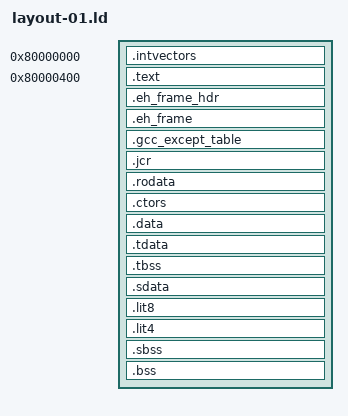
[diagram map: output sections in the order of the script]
/* ========================================================================
 *
 * n64.ld -- Libdragon linker script
 *
 * Originally based on n64ld.x, developed by Frank Somers <frank@g0dev.com>,
 * with modifications by hcs (halleyscometsoftware@hotmail.com),
 * released under the Unlicense.
 * ========================================================================
 */

OUTPUT_FORMAT ("elf32-bigmips", "elf32-bigmips", "elf32-littlemips")
OUTPUT_ARCH (mips)
EXTERN (_start)
ENTRY (_start)

PHDRS
{
    irq PT_LOAD AT ( 0x80000000 );
    main PT_LOAD AT ( 0x80000400 );
}

SECTIONS {
    .intvectors 0x80000000 : {
        . = ALIGN(32);
        KEEP(*(.intvectors))
        __intvectors_end = .;
    } :irq

    /* The text section carries the app code and its relocation addr is
    * the first byte of the cart domain in cached, unmapped memory
    */
    .text 0x80000400 : {
        __text_start = .;
        *(.boot)
        . = ALIGN(16);
        *(.text)
        /* MipsFit: verified unique input sections; GC remains enabled */
        *(.text._ZN3e64L16mesh_composePartEPKNS_4MeshEPKNS_15RenderTransformEPNS_7Vector3EPNS_10QuaternionES7_)
        *(.text._ZN3e6412water_updateEf)
        *(.text.joypad_get_axis_pressed)
        *(.text._ZN3e6420quaternion_toMatrix3EPKNS_10QuaternionE)
        *(.text._ZN3e6413aabb_overlapsEPKNS_4AABBES2_)
        *(.text.data_cache_hit_writeback)
        *(.text._ZSt14get_unexpectedv)
        *(.text.rdpq_set_mode_standard)
        *(.text.enable_interrupts)
        *(.text.joypad_get_axis_values.constprop.0)
        *(.text.samplebuffer_is_inited)
        *(.text.t3d_skeleton_update)
        *(.text.t3d_matrix_set_proj)
        *(.text.usb_everdrive_usbbusy)
        *(.text._ZN3e6417rigidBody_isAwakeEPKNS_9RigidBodyE)
        *(.text._ZN3e64L20render_scrollTextureEPK11T3DMaterialPKNS_7Vector2E)
        *(.text.t3d_segment_set)
        *(.text._ZN3e6426dynamicAABBTree_getFatAABBEPKNS_15DynamicAABBTreeEl)
        *(.text._ZN3e6411character3d9Animation19setJumpFootingSpeedERNS_11Character3DE)
        *(.text._exit)
        *(.text._ZN3e6420mesh_bindDeformFrameEPNS_4MeshEh)
        *(.text.rspq_highpri_begin)
        *(.text.__rdpq_fixup_mode)
        *(.text._ZN3e6422capsuleToStaticCapsuleEPNS_15ContactManifoldEPKNS_7CapsuleEPKNS_9TransformES4_S7_)
        *(.text.rdpq_tex_upload)
        *(.text.joybus_exec_async)
        *(.text._ZN3e6414stage2d_createEPKNS_10Stage2DDefEPNS_8Entity2DE)
        *(.text._ZN3e6411character3d6weapon5drawnEPKNS_11Character3DE)
        *(.text._ZN3e648entity3d17setMatrixFromBodyEPNS_8Entity3DEh)
        *(.text.audio_get_num_buffers)
        *(.text._ZN3e649mesh_cullEPNS_4MeshEPK11T3DViewport)
        *(.text._ZL24gameState_updateGameplayv)
        *(.text._ZN3e64L12water_scrollEPNS_7Vector2EPKfff)
        *(.text._ZN3e6414viewport_clearE7color_t)
        *(.text._ZN3e6411character3dL14weaponModifierEP11T3DSkeletonPv)
        *(.text.rdpq_text_printf)
        *(.text.emux_write)
        *(.text.t3d_mat4_from_srt_euler)
        *(.text._ZN3e6411character3d9Animation7getClipEh)
        *(.text.__rdpq_clear)
        *(.text._ZN3e6421physicsIsland_addBodyEPNS_13PhysicsIslandEPNS_9RigidBodyE)
        *(.text._ZN3e64L10insertLeafEPNS_15DynamicAABBTreeEl)
        *(.text._ZN3e6424mesh_materialHasVertexFxEh)
        *(.text._ZN3e6415viewport_attachEv)
        *(.text._ZN3e6422segment_closestToPointEPKNS_7Vector3ES2_S2_)
        *(.text._ZN3e6411character3d7physicsL19floorProbe_considerEPNS1_10FloorProbeEPKNS_7Vector3EfS6_.isra.0)
        *(.text.t3d_dmem_set_u16)
        *(.text._ZN3e646camera8getRightEPKNS_6CameraE)
        *(.text.get_ticks)
        *(.text._ZN3e6410controller3getEv)
        *(.text._ZN3e6423matrix3_transformVectorEPKNS_7Matrix3EPKNS_7Vector3E)
        *(.text._ZN3e648entity2d7destroyEPNS_8Entity2DE)
        *(.text._ZN3e6429transform_mulVectorTransposedEPKNS_9TransformEPKNS_7Vector3E)
        *(.text.joypad_poll)
        *(.text.__xorshift64)
        *(.text._ZN3e6416meshDeform_applyEPKNS_10MeshDeformEh)
        *(.text.t3d_tri_draw_strip)
        *(.text.__rdpq_write8_syncchange)
        *(.text._ZN3e6422contactSolver_shutdownEPNS_13ContactSolverE)
        *(.text.fm_cosf)
        *(.text._ZN3e6417transform_productEPKNS_9TransformES2_)
        *(.text.t3d_mat4fp_from_srt)
        *(.text._ZN3e6418quaternion_productEPKNS_10QuaternionES2_)
        *(.text._ZN3e6418sprite_loadTextureEPKNS_6SpriteE)
        *(.text._ZN3e6411character3d9Animation9setParamsERNS_11Character3DEf)
        *(.text.__rdpq_texture_rectangle_offline)
        *(.text._ZN3e6422broadPhase_testOverlapEPKNS_10BroadPhaseEll)
        *(.text._ZN3e6411ease_linearEf)
        *(.text.t3d_matrix_set)
        *(.text.t3d_dmem_set_u32)
        *(.text._ZN3e6420matrix3_outerProductEPKNS_7Vector3ES2_)
        *(.text.joypad_get_buttons_held)
        *(.text._ZN3e6415matrix3_inverseEPKNS_7Matrix3E)
        *(.text.display_set_fps_limit)
        *(.text._ZN3e6414matrix3_scaledEPKNS_7Matrix3Ef)
        *(.text.t3d_mat4_from_srt)
        *(.text.rdpq_paragraph_builder_span)
        *(.text._ZN3e6411character3d9Animation11getGaitAxisERKNS_11Character3DEf)
        *(.text.mixer_ch_play)
        *(.text._ZN3e6411sphereToBoxEPNS_15ContactManifoldEPNS_12PhysicsShapeES3_)
        *(.text._ZN10__cxxabiv112__unexpectedEPFvvE)
        *(.text.rdpq_fence)
        *(.text._ZN3e6416physicsHeap_initEPNS_11PhysicsHeapE)
        *(.text.startup.__dl_register_inspector)
        *(.text.kirq_wait)
        *(.text._ZN3e6410controller19getCStickNormalizedEPKNS_10ControllerE)
        *(.text.audio_write_begin)
        *(.text.fm_atan2f)
        *(.text._ZN3e6420physicsHeap_allocateEPNS_11PhysicsHeapEl)
        *(.text._ZN3e6423quaternion_rotateVectorEPKNS_10QuaternionEPKNS_7Vector3E)
        *(.text._ZN3e6424scene3d_updateCharactersEh)
        *(.text._ZN3e6417viewport_getScaleEv)
        *(.text._ZN3e6420rigidBody_canCollideEPKNS_9RigidBodyES2_)
        *(.text._ZN3e6415matrix3_productEPKNS_7Matrix3ES2_)
        *(.text._ZN3e6422rigidBody_getTransformEPKNS_9RigidBodyE)
        *(.text.seekfn_none)
        *(.text.rdpq_triangle)
        *(.text._ZN3e6418scene3d_getPhysicsEv)
        *(.text.kirq_begin_wait_vi)
        *(.text._ZN10__cxxabiv117__class_type_infoD2Ev)
        *(.text.t3d_mat4_mul_vec3)
        *(.text.t3d_light_set_count)
        *(.text.joybus_identify_callback)
        *(.text._ZN3e6420rigidBody_setToAwakeEPNS_9RigidBodyE)
        *(.text._ZN3e6411character3d6createEPKNS0_3DefEPNS_8Entity3DE)
        *(.text.rspq_highpri_end)
        *(.text.joybus_identify_async.part.0)
        *(.text._ZN3e646player6updateEv)
        *(.text._ZN3e6411box_raycastEPKNS_3BoxEPKNS_9TransformEPNS_11RaycastDataE)
        *(.text._ZL23gameState_enterMainMenuv)
        *(.text.fm_sinf)
        *(.text._ZN3e6411character3d9Animation12getGaitParamEfPKNS0_16MovementSettingsE)
        *(.text._ZN3e6412viewport_getEv)
        *(.text.t3d_mat4_to_frustum)
        *(.text._ZN3e646camera9springArm6updateEPNS_6CameraEPNS_7Vector3Ef)
        *(.text._ZN3e6421physicsStack_allocateEPNS_12PhysicsStackEl)
        *(.text._ZN3e6411character3d8movement7setModeEPNS0_8MovementEh)
        *(.text._ZN3e6411character2d9animation4freeEPNS_11Character2DE)
        *(.text._ZN3e6414ease_cubic_outEf)
        *(.text.__cxa_get_globals_fast)
        *(.text._ZN3e64L16render_runPiecesEPKNS_13RenderContextEPKttPPK11T3DSkeletonPPK9T3DMat4FP.constprop.0)
        *(.text.joybus_msg_send)
        *(.text._ZN3e6420meshDeform_bindFrameEPKNS_10MeshDeformEh)
        *(.text._ZN3e6422mesh_setMatrixFromBodyEPNS_4MeshEPKNS_7Vector3EPKNS_10QuaternionES4_h)
        *(.text.sinf_approx)
        *(.text.__rdpq_fixup_mode4)
        *(.text._ZN3e6417mesh_updateDeformEPNS_4MeshEh)
        *(.text.display_get_fps)
        *(.text.rspq_next_buffer)
        *(.text._ZN3e6423triangle_closestToPointEPKNS_7Vector3ES2_S2_S2_)
        *(.text._ZN3e6423collisionMesh_queryAABBEPKNS_13CollisionMeshEPvPFiS3_lENS_4AABBE)
        *(.text._ZN3e6418vector3_normalizedEPKNS_7Vector3E)
        *(.text._ZN3e6411character3d7physicsL15collectTriangleEPvl)
        *(.text.t3d_mat4_to_fixed_3x4)
        *(.text._ZN3e6427transform_productTransposedEPKNS_9TransformES2_)
        *(.text._ZN3e6417aabb_containsAABBEPKNS_4AABBES2_)
        *(.text._ZN3e6432broadPhase_insertShape_fromWorldEPNS_12PhysicsWorldEPNS_12PhysicsShapeENS_4AABBE)
        *(.text.tpx_matrix_push)
        *(.text.t3d_model_bvh_query_frustum)
        *(.text.t3d_mat4_to_fixed)
        *(.text._ZN3e6417physicsStack_freeEPNS_12PhysicsStackEPv)
        *(.text._ZN3e647fog_setEPNS_3FogE)
        *(.text._ZN3e6411character3d9Animation14setActiveNodesEv)
        *(.text.t3d_matrix_pop)
        *(.text.joypad_is_connected)
        *(.text._ZN3e646renderEv)
        *(.text.__rdpq_fixup_mode3)
        *(.text.hook_stdio_calls)
        *(.text.t3d_tri_draw_unindexed)
        *(.text.t3d_mat4_mul)
        *(.text._ZN3e6420quaternion_fromEulerEfff)
        *(.text._ZN3e6425collisionMesh_getTriangleEPKNS_13CollisionMeshElPNS_8TriangleE)
        *(.text._ZN3e6424particleBuffer_setMatrixEPNS_14ParticleBufferEPKfS3_S3_h)
        *(.text._ZN3e6411time_updateEv)
        *(.text._ZN3e6414particles_drawEv)
        *(.text._ZN3e6419aabb_closestToPointEPKNS_4AABBEPKNS_7Vector3E)
        *(.text.joypad_read_callback)
        *(.text.__retarget_lock_release_recursive)
        *(.text.joypad_get_buttons_pressed)
        *(.text._ZN3e6411character3d9Animation13setJumpParamsERNS_11Character3DEf)
        *(.text._ZL24gameState_updateGameOverv)
        *(.text._ZN3e648entity3d9setMatrixEPNS_8Entity3DEh)
        *(.text._ZN3e644menu7controlL7getStepENS1_13MenuDirectionEbb)
        *(.text.rdpq_text_get_font)
        *(.text.joypad_inputs_from_n64_controller_read)
        *(.text.exception_reset_time)
        *(.text._ZN3e6413gameState_getEh)
        *(.text.__rdpq_set_mode_fill)
        *(.text.t3d_matrix_push)
        *(.text.t3d_matrix_stack)
        *(.text.rdpq_mode_end)
        *(.text.rdpq_detach_cb)
        *(.text._ZN3e6410angle_wrapEf)
        *(.text.__rdpq_texture_rectangle)
        *(.text._ZN3e6413box_testPointEPKNS_3BoxEPKNS_9TransformEPKNS_7Vector3E)
        *(.text._ZN3e6411character3d9Animation18setLocomotionParamERNS_11Character3DEf)
        *(.text.mips_disasm)
        *(.text.rdpq_sync_full)
        *(.text._ZN3e6411character3d11getBonePoseEPK11T3DSkeletonsP9fm_vec3_tP9fm_quat_t)
        *(.text.bvh_query_node)
        *(.text._ZN3e646camera9springArm8getPitchEPKNS_6CameraE)
        *(.text._ZN3e646player21setCharacter3DControlENS_8PlayerIDEPNS_8ViewportE)
        *(.text._ZN3e6411character3d7control6updateEPNS_11Character3DEPNS0_15MovementCommandEPKNS0_8ControlsEf)
        *(.text._ZN3e6418capsuleToStaticBoxEPNS_15ContactManifoldEPKNS_7CapsuleEPKNS_9TransformEPKNS_3BoxES7_)
        *(.text._ZN10__cxxabiv120__si_class_type_infoD0Ev)
        *(.text._ZN3e6422dynamicAABBTree_updateEPNS_15DynamicAABBTreeElNS_4AABBE)
        *(.text.rdpq_set_color_image)
        *(.text._ZNK3e6411character3d15AnimationBuffer11blendLayersEPK11T3DSkeleton)
        *(.text._ZN3e6419physicsIsland_solveEPNS_13PhysicsIslandE)
        *(.text._ZN3e644menu7control4readEPNS0_8ControlsEPKNS_10ControllerEPKNS0_14ControlBindingE)
        *(.text._ZN3e6418menuStack_setIndexEa)
        *(.text._ZN3e6411character3d9Animation13evaluateGraphEf)
        *(.text.waveform_vadpcm_read_compressed.isra.0)
        *(.text.display_get)
        *(.text.rdpq_mode_antialias)
        *(.text._ZN3e6411scene2d_getEv)
        *(.text.rdpq_set_z_image)
        *(.text._ZN3e6447contactManager_removeContactsFromBody_fromWorldEPNS_12PhysicsWorldEPNS_9RigidBodyE)
        *(.text.__rdpq_font_glyph)
        *(.text.timer_callback)
        *(.text.timer_update_compare)
        *(.text._ZNSt9type_infoD2Ev)
        *(.text._ZN3e6410controller6isHeldEPKNS_10ControllerENS_8ButtonIDE)
        *(.text.vi_set_origin)
        *(.text._ZN3e6417broadPhase_updateEPNS_10BroadPhaseElNS_4AABBE)
        *(.text.__rdpq_block_run_with_rdp)
        *(.text.fm_expf)
        *(.text.__rdpq_write8_syncchangeuse)
        *(.text.audio_get_buffer_length)
        *(.text._ZN3e6410controller18getStickNormalizedEPKNS_10ControllerE)
        *(.text._ZN3e6422broadPhase_updateShapeEPNS_12PhysicsWorldElNS_4AABBE)
        *(.text.audio_get_queued_buffers)
        *(.text.__entropy_add)
        *(.text._ZN3e6411character3d9Animation18setLocomotionSpeedERNS_11Character3DEf)
        *(.text._ZN3e6418mesh_setPartOffsetEPNS_4MeshEhPKNS_15RenderTransformE)
        *(.text.__retarget_lock_acquire_recursive)
        *(.text._ZN3e6414mesh_setMatrixEPNS_4MeshEPKNS_15RenderTransformEh)
        *(.text._ZN3e6412ease_quad_inEf)
        *(.text._ZN3e6411character3d7physics7collideEPNS_11Character3DEPKNS_12PhysicsWorldE)
        *(.text.vi_write_begin)
        *(.text._ZN3e6411character3d9Animation10setFootingERNS_11Character3DE)
        *(.text.__mixer_round_wait)
        *(.text._ZN3e646camera14getAngleAroundEPKNS_6CameraEPKNS_7Vector3E)
        *(.text._ZN3e648time_getEv)
        *(.text.audio_callback.part.0)
        *(.text._ZN3e6410controllerL10readButtonEPK16joypad_buttons_uNS_8ButtonIDE)
        *(.text.mixer_try_play)
        *(.text._ZN3e6412scene2d_loadEPKNS_10Scene2DDefE)
        *(.text.__rdpq_clear_z_with_rsp)
        *(.text._ZN3e6411character3d9Animation14closeIdleClipsEv)
        *(.text._ZN3e6429contactManager_testCollisionsEPNS_14ContactManagerE)
        *(.text._ZN3e648boxToBoxEPNS_15ContactManifoldEPNS_12PhysicsShapeES3_)
        *(.text.fm_sincosf)
        *(.text.rdpq_font_render_paragraph)
        *(.text._ZN3e6416propSound_updateEPNS_12PhysicsWorldE)
        *(.text._ZN3e6425physicsWorld_markNewShapeEPNS_12PhysicsWorldE)
        *(.text.rdpq_mode_persp)
        *(.text._ZN3e6411character3d9Animation13syncGridClipsEPKNS0_13AnimationNodeEff)
        *(.text._ZN3e6424uiAnimationPlayer_updateEPNS_17UIAnimationPlayerEPNS_7Scene2DEf)
        *(.text.timer_init)
        *(.text._ZN3e6420physicsStack_reserveEPNS_12PhysicsStackEm)
        *(.text.t3d_vec3_norm)
        *(.text.__rdpq_reset_render_mode)
        *(.text._ZN3e6429viewport_setPerspectiveCameraEv)
        *(.text.__rdpq_fixup_write8_syncchange)
        *(.text.t3d_light_set_point)
        *(.text.rdpq_paragraph_free)
        *(.text._ZN3e646camera6updateEPNS_6CameraEPNS_7Vector3EPKNS_7Scene3DEf)
        *(.text._ZN3e6427dynamicAABBTree_getUserDataEPKNS_15DynamicAABBTreeEl)
        *(.text.rdpq_text_printn)
        *(.text._ZN3e6420skeleton_getBonePoseEPK11T3DSkeletonsP9fm_vec3_tP9fm_quat_t)
        *(.text._ZN3e64L33springBoneCollision_collideSphereEPKNS_7Vector3EfbffS2_.isra.0)
        *(.text._ZN3e64L16mesh_writeMatrixEP9T3DMat4FPPKNS_7Vector3EPKNS_10QuaternionES4_)
        *(.text.__rdpq_autosync_change)
        *(.text.t3d_quat_nlerp)
        *(.text._ZN3e649collisionEPNS_15ContactManifoldEPNS_12PhysicsShapeES3_)
        *(.text.__vi_interrupt)
        *(.text.t3d_viewport_look_at)
        *(.text._ZN3e6411character3d7physics8syncBodyEPNS_11Character3DE)
        *(.text._ZN3e6424physicsShape_computeAABBEPKNS_12PhysicsShapeEPNS_4AABBE)
        *(.text._ZN3e6433rigidBody_setTransformPositionYawEPNS_9RigidBodyENS_7Vector3Ef)
        *(.text.rdpq_text_register_font)
        *(.text._ZN3e6424segment_closestToSegmentEPKNS_7Vector3ES2_S2_S2_PS0_S3_)
        *(.text._ZN3e6411character2d8movementL13setLocomotionEPNS_11Character2DEPNS0_15MovementCommandEf)
        *(.text.__rdpq_set_color_image)
        *(.text._ZN3e6411character3d7control4readEPNS0_8ControlsEPKNS0_14ControlBindingE)
        *(.text._ZN3e6419contactSolver_solveEPNS_13ContactSolverE)
        *(.text._ZN3e6417capsuleToTriangleEPNS_15ContactManifoldEPKNS_7CapsuleEPKNS_9TransformEPKNS_8TriangleE)
        *(.text._ZN3e6427rigidBody_setLinearVelocityEPNS_9RigidBodyENS_7Vector3E)
        *(.text._ZN3e6414physics_updateEPNS_12PhysicsWorldEf)
        *(.text.__rdpq_write8)
        *(.text.t3d_viewport_set_projection)
        *(.text._ZN3e6411character2d7physics7collideEPNS_11Character2DE)
        *(.text.rdpq_mode_fog)
        *(.text.rdpq_font_load_buf)
        *(.text.set_VI_interrupt)
        *(.text._ZN3e6418mesh_getPartMatrixEPKNS_4MeshEhh)
        *(.text.kmutex_lock)
        *(.text._ZN3e6416particles_updateEh)
        *(.text._ZL28staminaWheel_setRenderStateBv)
        *(.text.si_interrupt)
        *(.text.t3d_light_set_ambient)
        *(.text.__cxa_get_globals)
        *(.text._ZN3e6412game_runStepEv)
        *(.text._ZN3e6414viewport_has3DEv)
        *(.text.mixer_channel_volumes)
        *(.text.tpx_matrix_pop)
        *(.text._ZN3e6411character3d9Animation13getTurningAvgEPKNS0_17AnimationSettingsEff)
        *(.text.decompress_shrinkler_read)
        *(.text.rdpq_mode_push)
        *(.text.__vi_validate_config)
        *(.text.__MI_handler)
        *(.text._ZNKSt9type_info14__is_pointer_pEv)
        *(.text.usblog_write)
        *(.text._ZN3e649light_getEv)
        *(.text._ZN3e6418mesh_materialBlockEh)
        *(.text.__rdpq_mode_change_som)
        *(.text.rdpq_mode_pop)
        *(.text._ZN3e6424contactSolver_initializeEPNS_13ContactSolverEPNS_13PhysicsIslandE)
        *(.text.mixer_set_vol)
        *(.text.joypad_get_buttons_released)
        *(.text._ZN3e6422quaternion_toAxisAngleEPKNS_10QuaternionEPNS_7Vector3EPf)
        *(.text._ZN3e6412physics_stepEPNS_12PhysicsWorldE)
        *(.text._ZN3e649light_setEPKNS_8LightDefE)
        *(.text._ZN3e6415viewport_detachEv)
        *(.text._ZN3e6419contactManager_initEPNS_14ContactManagerEPNS_12PhysicsStackE)
        *(.text.rewind_anim)
        *(.text.display_get_width)
        *(.text.vi_show)
        *(.text._ZL27staminaWheel_setRenderStatePK12StaminaWheel)
        *(.text.texload_block_8bpp)
        *(.text.rspq_block_run)
        *(.text.internal_open)
        *(.text._ZN3e646camera5resetEPNS_6CameraE)
        *(.text.__rdpq_clear_z)
        *(.text.texload_recalc_tileparms)
        *(.text.__TI_handler)
        *(.text.__RESET_handler)
        *(.text.t3d_viewport_attach)
        *(.text.__ioctl)
        *(.text.graphics_set_color)
        *(.text.get_interrupts_state)
        *(.text.__rdpq_block_run_no_rdp)
        *(.text._ZN3e6411character3d9Animation18getLocomotionPhaseEPKNS0_17AnimationSettingsEff)
        *(.text._ZN3e6428rigidBody_synchronizeProxiesEPNS_9RigidBodyE)
        *(.text._ZN3e6412sound_updateEv)
        *(.text.console_set_render_mode)
        *(.text.startup.main)
        *(.text.t3d_frame_start)
        *(.text._ZN3e6412debugUI_drawEv)
        *(.text.decompress_aplib_partial.part.0)
        *(.text._ZN3e648entity3d12setTransformEPNS_8Entity3DEPKNS_11character3d13KinematicBodyE)
        *(.text._ZN3e646camera7control6updateEPNS_6CameraEPKNS0_14ControlBindingEPKNS_7Scene3DEf)
        *(.text.t3d_vec3_cross)
        *(.text._ZN3e6411Character3D14updateMovementEPNS_11character3d15MovementCommandEf)
        *(.text._ZN3e6425dynamicAABBTree_queryAABBEPKNS_15DynamicAABBTreeEPvPFiS3_lENS_4AABBE)
        *(.text._ZL25gameState_enterGameplay2Dv)
        *(.text._ZL21staminaWheel_setInputPN3e648ParticleEh)
        *(.text._ZN3e6411character3d5sound6updateEPNS_11Character3DE)
        *(.text.mixer_ch_alloc)
        *(.text._ZN3e6411character3d8movementL13setLocomotionEPNS_11Character3DEPNS0_15MovementCommandEf)
        *(.text._ZN3e6411character2d8movementL10setRollingEPNS_11Character2DEPNS0_15MovementCommandEf)
        *(.text._ZN3e647fog_getEv)
        *(.text._ZN3e6410controller4pollEv)
        *(.text._ZN3e6413ease_cubic_inEf)
        *(.text.vi_write_end)
        *(.text.__rdpq_fill_rectangle_offline)
        *(.text._ZN3e6421capsuleToStaticSphereEPNS_15ContactManifoldEPKNS_7CapsuleEPKNS_9TransformEPKNS_6SphereES7_)
        *(.text.rspq_flush)
        *(.text.display_try_get)
        *(.text._ZL13demangle_namePc)
        *(.text.rdpq_mode_filter)
        *(.text.decompress_lz4_read)
        *(.text.display_show)
        *(.text.tpx_particle_draw_s8)
        *(.text._ZN3e6417sprite_drawLoadedEPKNS_6SpriteENS_7Vector2ES3_)
        *(.text.rdpq_text_vprintf)
        *(.text.joypad_accessory_polled)
        *(.text.rdpq_paragraph_build)
        *(.text._ZN3e646player3getEv)
        *(.text.__rdpq_paragraph_builder_update_bbox_width.part.0)
        *(.text._ZN3e648game_getEv)
        *(.text.joybus_get_identifier)
        *(.text.t3d_mat4_perspective)
        *(.text._ZN3e6411character2d9animation6updateEPNS_11Character2DEf)
        *(.text.joypad_get_inputs)
        *(.text.data_cache_hit_invalidate)
        *(.text.joypad_read_async.part.0)
        *(.text.__rand64)
        *(.text._ZN3e6411scene3d_getEv)
        *(.text._ZN3e6417vector3_normalizeEPNS_7Vector3E)
        *(.text.rspq_flush_internal)
        *(.text._ZN3e6424quaternion_fromAxisAngleEPKNS_7Vector3Ef)
        *(.text._ZN3e64L11shapeToMeshEPNS_15ContactManifoldEPNS_12PhysicsShapeES3_)
        *(.text.graphics_draw_box)
        *(.text._ZN3e6414menuStack_initEv)
        *(.text._ZN3e6414buoyancy_applyEPNS_12PhysicsWorldEPKNS_14BuoyancyVolumeE)
        *(.text._ZN3e6422physicsShape_testPointEPKNS_12PhysicsShapeEPKNS_7Vector3E)
        *(.text.vi_write_masked)
        *(.text.timer_poll)
        *(.text._ZN3e649time_initEv)
        *(.text._ZN3e6410sound_pollEv)
        *(.text.__rsp_crash)
        *(.text.set_SI_interrupt)
        *(.text.__display_callback)
        *(.text._ZN3e6430contactManager_findNewContactsEPNS_14ContactManagerE)
        *(.text._ZN3e6411character3d8movementL21setHorizontalVelocityEPNS_11Character3DEffff)
        *(.text._ZN3e6418capsule_getSegmentEPKNS_7CapsuleEPKNS_9TransformEPNS_7Vector3ES7_)
        *(.text.rdpq_mode_begin)
        *(.text.rdpq_paragraph_builder_end)
        *(.text._ZN3e6422broadPhase_insertShapeEPNS_10BroadPhaseEPNS_12PhysicsShapeENS_4AABBE)
        *(.text._ZN3e6410controller9isPressedEPKNS_10ControllerENS_8ButtonIDE)
        *(.text._ZL25gameState_controlGameplayv)
        *(.text.inspector_stdout)
        *(.text.rdpq_paragraph_builder_begin)
        *(.text._ZN3e6411character3d5stats6updateEPNS_11Character3DEPKNS0_15MovementCommandEf)
        *(.text.usb_initialize)
        *(.text.attach)
        *(.text._ZN3e6423skeletonModifiers_applyEPNS_17SkeletonModifiersEP11T3DSkeleton)
        *(.text._ZN3e6411character3d9Animation12getGridClipsEPKNS0_13AnimationNodeEffPh)
        *(.text.mixer_ch_seek)
        *(.text._ZN3e6420vector3_computeBasisEPKNS_7Vector3EPS0_S3_)
        *(.text._ZN3e6416viewport_close3DEv)
        *(.text.audio_write_end)
        *(.text.usb_sc64_read)
        *(.text._ZN3e6411character3d9Animation21setStrafeLockedParamsERNS_11Character3DEf)
        *(.text.symt_get_string)
        *(.text.joypad_vi_interrupt_callback)
        *(.text.mixer_emit_channel)
        *(.text.lseek)
        *(.text._ZN3e649ui_updateEPKNS_11UIAnimationE)
        *(.text.usb_write)
        *(.text.t3d_mat4_look_at)
        *(.text.__rsp_check_assert)
        *(.text._ZN3e6411character3d15AnimationBuffer8addLayerEPK11T3DSkeletonf.part.0)
        *(.text._ZN3e6417vector3_magnitudeEPKNS_7Vector3E)
        *(.text.draw_cb.3)
        *(.text._ZN3e6411Character3D12setAnimationEv)
        *(.text._ZN3e6411character3d8movement12isLocomotionEh)
        *(.text.rdpq_paragraph_builder_font)
        *(.text._ZN3e648camera2d8toScreenEPKNS_8Camera2DENS_7Vector2Ef)
        *(.text.usb_everdrive_read)
        *(.text.rdpq_attach)
        *(.text._ZN3e6424scene2d_setRenderContextEPKNS_7Scene2DEPNS_13RenderContextE)
        *(.text._ZN3e6410controller10isReleasedEPKNS_10ControllerENS_8ButtonIDE)
        *(.text._ZN3e6411character3d9Animation15setStrafeParamsERNS_11Character3DEf)
        *(.text.t3d_screen_clear_depth)
        *(.text._ZN3e6410time_resetEv)
        *(.text._ZN3e6413ease_quad_outEf)
        *(.text._ZN3e64L17mesh_localFrustumEP10T3DFrustumPKS0_PKNS_7Vector3EPKNS_10QuaternionES6_)
        *(.text.rdpq_mode_dithering)
        *(.text._ZN3e6422contactSolver_preSolveEPNS_13ContactSolverEf)
        *(.text.__rspq_deferred_poll)
        *(.text._ZN3e644menu7control6updateEv)
        *(.text.close)
        *(.text.t3d_viewport_set_perspective)
        *(.text.__rdpq_paragraph_build)
        *(.text._ZN3e6422quaternion_fromMatrix3EPKNS_7Matrix3E)
        *(.text.debug_assert_func)
        *(.text._ZN3e6419transform_mulVectorEPKNS_9TransformEPKNS_7Vector3E)
        *(.text._ZN3e6416ease_expo_in_outEf)
        *(.text.decompress_shrinkler_reset)
        *(.text._ZN3e6411character3d3aim5applyEP11T3DSkeletonPv)
        *(.text.__gxx_personality_v0)
        *(.text.unlikely._ZSt10unexpectedv)
        *(.text._ZN3e6411character3d9Animation15setAimingParamsERNS_11Character3DEf)
        *(.text.__rdpq_interrupt)
        *(.text.__vblank_interrupt)
        *(.text._ZN3e6424dynamicAABBTree_queryRayEPKNS_15DynamicAABBTreeEPvPFiS3_lEPNS_11RaycastDataE)
        *(.text.joypad_detect_callback)
        *(.text.acct_switch)
        *(.text._ZN3e6424physicsIsland_initializeEPNS_13PhysicsIslandE)
        *(.text._ZN3e6415debugUI_showFPSEv)
        *(.text.vi_get_refresh_rate)
        *(.text._ZN3e6416game_updateStateEv)
        *(.text.kirq_begin_wait_si)
        *(.text._ZN3e6430physicsPagedAllocator_shutdownEPNS_21PhysicsPagedAllocatorE)
        *(.text.audio_callback)
        *(.text._ZN3e6411character3d9Animation13setSwimParamsERNS_11Character3DEf)
        *(.text.pi_poll)
        *(.text._ZN3e6411character3d9Animation12setRollParamERNS_11Character3DEf)
        *(.text._ZN3e6411character3d9Animation14setClimbParamsERNS_11Character3DEf)
        *(.text.__wrap___do_global_ctors)
        *(.text.mixer_ramp_linear)
        *(.text.startup.__ktls_constructor)
        *(.text.t3d_frustum_vs_aabb_s16)
        *(.text._ZN3e6424scene3d_setRenderContextEPKNS_7Scene3DEPNS_13RenderContextEPKNS_8ViewportE)
        *(.text._ZN3e646camera7controlL17setSpringArmInputEPNS_6CameraEff)
        *(.text._ZN3e6416ease_quad_in_outEf)
        *(.text.__rdpq_set_fill_color)
        *(.text._ZN3e6421aabb_closestToSegmentEPKNS_4AABBEPKNS_7Vector3ES5_)
        *(.text.display_get_zbuf)
        *(.text.mixer_poll_async)
        *(.text._ZN3e649font_initEPKNS_7FontDefEh)
        *(.text._ZN3e6427collision_fixTriangleNormalEPKNS_8TriangleEPKNS_7Vector3ES5_S5_)
        *(.text._ZN3e6432contactConstraint_solveCollisionEPNS_17ContactConstraintE)
        *(.text._ZN3e6427rigidBody_calculateMassDataEPNS_9RigidBodyE)
        *(.text._ZN3e6416springBone_applyEP11T3DSkeletonPv)
        *(.text.rdpq_detach_show)
        *(.text.rdpq_paragraph_render)
        *(.text.tpx_matrix_set)
        *(.text.t3d_anim_update)
        *(.text._ZN3e6412aabb_combineEPKNS_4AABBES2_)
        *(.text._ZN3e6418matrix3_differenceEPKNS_7Matrix3ES2_)
        *(.text.disable_interrupts)
        *(.text._ZN3e6411character2d7control4readEPNS0_8ControlsEPKNS0_14ControlBindingE)
        *(.text._ZL18gameState_canLeavev)
        *(.text.t3d_tri_draw)
        *(.text._ZN3e6423mesh_materialIsDeferredEh)
        *(.text.__cxa_rethrow)
        *(.text.debug_backtrace)
        *(.text._ZN3e6422broadPhase_updatePairsEPNS_10BroadPhaseE)
        *(.text.tpx_particle_draw_generic_s16)
        *(.text.t3d_viewport_get)
        *(.text.rspq_switch_context)
        *(.text.joypad_poll.part.0)
        *(.text.__rdpq_set_scissor)
        *(.text._ZL26gameState_updateGameplay2Dv)
        *(.text._ZN3e6422cloth_blendRenderStateEPNS_5ClothEf)
        *(.text.__thlist_splice_pri)
        *(.text.is_wrap_break_char)
        *(.text._ZN3e6411character3d7physicsL7recoverEPNS_11Character3DEPKNS_12PhysicsWorldEPNS1_14CollisionStateE.constprop.0)
        *(.text._ZN3e6413game_setStateEPNS_4GameEh)
        *(.text.vi_write_idx_masked)
        *(.text._ZN3e6411character3d9Animation10snapToJumpEv)
        *(.text._ZN3e6419capsule_computeAABBEPKNS_7CapsuleEPKNS_9TransformEPNS_4AABBE)
        *(.text._ZN3e6411character3d9Animation9initGraphERNS_11Character3DE)
        *(.text.rdpq_font_free)
        *(.text._ZN3e6411character3d6weapon8setBonesEPNS_11Character3DE)
        *(.text._ZN3e6419angle_wrap_relativeEff)
        *(.text._ZN3e6417ease_cubic_in_outEf)
        *(.text._ZN3e6421physicsStack_shutdownEPNS_12PhysicsStackE)
        *(.text._ZNK10__cxxabiv120__si_class_type_info12__do_dyncastEiNS_17__class_type_info10__sub_kindEPKS1_PKvS4_S6_RNS1_16__dyncast_resultE)
        *(.text.samplebuffer_get)
        *(.text._ZN3e6433matrix3_transformVectorTransposedEPKNS_7Matrix3EPKNS_7Vector3E)
        *(.text._ZN3e6414particles_initEv)
        *(.text.graphics_fill_screen)
        *(.text.inspector_page_fpr)
        *(.text.__rdpq_fill_rectangle)
        *(.text._ZN3e6412ease_expo_inEf)
        *(.text._ZN3e6413ease_expo_outEf)
        *(.text._ZN3e6416matrix3_diagonalEfff)
        *(.text._ZN3e6415matrix3_setRowsEPNS_7Matrix3EPKNS_7Vector3ES4_S4_)
        *(.text._ZN3e6411matrix3_sumEPKNS_7Matrix3ES2_)
        *(.text._ZN3e6419quaternion_identityEv)
        *(.text._ZN3e6421quaternion_normalizedEPKNS_10QuaternionE)
        *(.text._ZN3e6420quaternion_integrateEPNS_10QuaternionEPKNS_7Vector3Ef)
        *(.text._ZN3e6417vector2_magnitudeEPKNS_7Vector2E)
        *(.text._ZN3e6416aabb_surfaceAreaEPKNS_4AABBE)
        *(.text._ZN3e6411raycast_setEPNS_11RaycastDataEPKNS_7Vector3ES4_f)
        *(.text._ZN3e6416triangle_raycastEPKNS_8TriangleEPNS_11RaycastDataE)
        *(.text._ZN3e6420physicsHeap_shutdownEPNS_11PhysicsHeapE)
        *(.text._ZN3e6416physicsHeap_freeEPNS_11PhysicsHeapEPv)
        *(.text._ZN3e6426physicsPagedAllocator_initEPNS_21PhysicsPagedAllocatorEll)
        *(.text._ZN3e6430physicsPagedAllocator_allocateEPNS_21PhysicsPagedAllocatorE)
        *(.text._ZN3e6426physicsPagedAllocator_freeEPNS_21PhysicsPagedAllocatorEPv)
        *(.text._ZN3e6417physicsStack_initEPNS_12PhysicsStackE)
        *(.text._ZN3e6415box_computeAABBEPKNS_3BoxEPKNS_9TransformEPNS_4AABBE)
        *(.text._ZN3e6415box_computeMassEPKNS_3BoxEPKNS_9TransformEfPNS_8MassDataE)
        *(.text._ZN3e6417capsule_testPointEPKNS_7CapsuleEPKNS_9TransformEPKNS_7Vector3E)
        *(.text._ZN3e6415capsule_raycastEPKNS_7CapsuleEPKNS_9TransformEPNS_11RaycastDataE)
        *(.text._ZN3e6419capsule_computeMassEPKNS_7CapsuleEPKNS_9TransformEfPNS_8MassDataE)
        *(.text._ZN3e6423shapeDef_localTransformEPKNS_9TransformE)
        *(.text._ZN3e6420physicsShape_fromDefEPNS_12PhysicsShapeEPKNS_15PhysicsShapeDefENS_7Vector3E)
        *(.text._ZN3e6420physicsShape_releaseEPNS_12PhysicsShapeE)
        *(.text._ZN3e6420physicsShape_raycastEPKNS_12PhysicsShapeEPNS_11RaycastDataE)
        *(.text._ZN3e6424physicsShape_computeMassEPKNS_12PhysicsShapeEPNS_8MassDataE)
        *(.text._ZN3e6416sphere_testPointEPKNS_6SphereEPKNS_9TransformEPKNS_7Vector3E)
        *(.text._ZN3e6414sphere_raycastEPKNS_6SphereEPKNS_9TransformEPNS_11RaycastDataE)
        *(.text._ZN3e6418sphere_computeAABBEPKNS_6SphereEPKNS_9TransformEPNS_4AABBE)
        *(.text._ZN3e6418sphere_computeMassEPKNS_6SphereEPKNS_9TransformEfPNS_8MassDataE)
        *(.text._ZN3e6417rigidBodyDef_initEPNS_12RigidBodyDefE)
        *(.text._ZN3e6414rigidBody_initEPNS_9RigidBodyEPKNS_12RigidBodyDefEPNS_12PhysicsWorldE)
        *(.text._ZN3e6425rigidBody_removeAllShapesEPNS_9RigidBodyE)
        *(.text._ZN3e6426rigidBody_applyLinearForceEPNS_9RigidBodyENS_7Vector3E)
        *(.text._ZN3e6421rigidBody_applyTorqueEPNS_9RigidBodyENS_7Vector3E)
        *(.text._ZN3e6420rigidBody_setToSleepEPNS_9RigidBodyE)
        *(.text._ZN3e64L21rigidBody_attachShapeEPNS_9RigidBodyEPNS_12PhysicsShapeEPKNS_9TransformEfffi)
        *(.text._ZN3e6418rigidBody_addShapeEPNS_9RigidBodyEPKNS_15PhysicsShapeDefENS_7Vector3E)
        *(.text._ZN3e6420rigidBody_addCapsuleEPNS_9RigidBodyEPKNS_10CapsuleDefE)
        *(.text._ZN3e6423broadPhase_treeCallbackEPvl)
        *(.text._ZN3e64L15contactPair_cmpEPKvS1_)
        *(.text._ZN3e6415broadPhase_initEPNS_10BroadPhaseEPNS_14ContactManagerE)
        *(.text._ZN3e6419broadPhase_shutdownEPNS_10BroadPhaseE)
        *(.text._ZN3e6422broadPhase_removeShapeEPNS_10BroadPhaseEPKNS_12PhysicsShapeE)
        *(.text._ZN3e64L12allocateNodeEPNS_15DynamicAABBTreeE)
        *(.text._ZN3e64L13syncHierarchyEPNS_15DynamicAABBTreeEl)
        *(.text._ZN3e64L14deallocateNodeEPNS_15DynamicAABBTreeEl.part.0)
        *(.text._ZN3e64L10removeLeafEPNS_15DynamicAABBTreeEl)
        *(.text._ZN3e6420dynamicAABBTree_initEPNS_15DynamicAABBTreeE)
        *(.text._ZN3e6424dynamicAABBTree_shutdownEPNS_15DynamicAABBTreeE)
        *(.text._ZN3e6422dynamicAABBTree_insertEPNS_15DynamicAABBTreeENS_4AABBEPv)
        *(.text._ZN3e6422dynamicAABBTree_removeEPNS_15DynamicAABBTreeEl)
        *(.text._ZN3e64L12orthographicEffllPNS_10ClipVertexElS1_)
        *(.text._ZN3e64L13trackEdgeAxisEPllfPfNS_7Vector3EPS2_)
        *(.text._ZN3e64L11supportEdgeENS_9TransformENS_7Vector3ES1_PS1_S2_)
        *(.text._ZN3e64L25collision_collectTriangleEPvl)
        *(.text._ZN3e6414sphereToSphereEPNS_15ContactManifoldEPNS_12PhysicsShapeES3_)
        *(.text._ZN3e6412capsuleToBoxEPNS_15ContactManifoldEPNS_12PhysicsShapeES3_)
        *(.text._ZN3e6415sphereToCapsuleEPNS_15ContactManifoldEPNS_12PhysicsShapeES3_)
        *(.text._ZN3e6416capsuleToCapsuleEPNS_15ContactManifoldEPNS_12PhysicsShapeES3_)
        *(.text._ZN3e6420collisionMesh_deleteEPNS_13CollisionMeshE)
        *(.text._ZN3e6418collisionMesh_loadEPKc)
        *(.text._ZN3e64L25collisionMesh_raycastLeafEPvl)
        *(.text._ZN3e6421collisionMesh_raycastEPKNS_13CollisionMeshEPKNS_9TransformEPNS_11RaycastDataE)
        *(.text._ZN3e6423contactManifold_setPairEPNS_15ContactManifoldEPNS_12PhysicsShapeES3_)
        *(.text._ZN3e6423contactManager_shutdownEPNS_14ContactManagerE)
        *(.text._ZN3e6425contactManager_addContactEPNS_14ContactManagerEPNS_12PhysicsShapeES3_)
        *(.text._ZN3e6428contactManager_removeContactEPNS_14ContactManagerEPNS_17ContactConstraintE)
        *(.text._ZN3e6437contactManager_removeContactsFromBodyEPNS_14ContactManagerEPNS_9RigidBodyE)
        *(.text._ZN3e6424physicsIsland_addContactEPNS_13PhysicsIslandEPNS_17ContactConstraintE)
        *(.text._ZN3e6423physicsWorld_allocShapeEPNS_12PhysicsWorldEPPNS_12PhysicsShapeE)
        *(.text._ZN3e6422physicsWorld_freeShapeEPNS_12PhysicsWorldEPNS_12PhysicsShapeE)
        *(.text._ZN3e6432broadPhase_removeShape_fromWorldEPNS_12PhysicsWorldEPKNS_12PhysicsShapeE)
        *(.text._ZN3e6417physicsWorld_initEPNS_12PhysicsWorldEfNS_7Vector3El)
        *(.text._ZN3e6424physicsWorld_createClothEPNS_12PhysicsWorldEPKNS_8ClothDefE)
        *(.text._ZN3e6421physicsWorld_shutdownEPNS_12PhysicsWorldE)
        *(.text._ZN3e6423physicsWorld_createBodyEPNS_12PhysicsWorldEPKNS_12RigidBodyDefE)
        *(.text._ZN3e6420physicsWorld_setWindEPNS_12PhysicsWorldENS_7Vector3E)
        *(.text._ZN3e6424physicsWorld_addBuoyancyEPNS_12PhysicsWorldEPKNS_14BuoyancyVolumeE)
        *(.text._ZN3e64L19cloth_updateNormalsEPNS_5ClothE.part.0)
        *(.text._ZN3e6414cloth_isCulledEPKNS_5ClothE)
        *(.text._ZN3e6410cloth_stepEPNS_5ClothEf)
        *(.text._ZN3e6412cloth_deleteEPNS_5ClothE)
        *(.text._ZN3e6412cloth_createEPNS_5ClothEPKNS_13CollisionMeshEPKNS_8ClothDefE)
        *(.text._ZN3e64L18buoyancy_addSampleEPNS_13BuoyancyAccumEPKNS_14BuoyancyVolumeEPKNS_7Vector3ES7_S7_ff)
        *(.text._ZN3e6411character3d7destroyEPNS_11Character3DE)
        *(.text._ZN3e6411character3d3aim4initEPNS_11Character3DEPKNS0_14AimingSettingsE)
        *(.text._ZN3e6411character3d9Animation9closeClipEh)
        *(.text._ZN3e6411character3d9Animation8openClipEh)
        *(.text._ZN3e6411character3d9Animation24getLockedDirectionWeightERKNS_11Character3DEh)
        *(.text._ZN3e6411character3d9Animation16snapGridFromClipEhh)
        *(.text._ZN3e6411character3d9Animation22snapLocomotionFromGridEhf)
        *(.text._ZN3e6411character3d9Animation16setGridRowSpeedsEPKNS0_13AnimationNodeE)
        *(.text._ZN3e6411character3d9Animation16snapGridFromGridEhfh)
        *(.text._ZN3e6411character3d9Animation24getStrafeDirectionWeightERKNS_11Character3DEf)
        *(.text._ZN3e6411character3d9Animation15snapStrafeEntryEv)
        *(.text._ZN3e6411character3d9Animation14snapStrafeExitEv)
        *(.text._ZN3e6411character3d9Animation14syncLandToJumpEv)
        *(.text._ZN3e6411character3d9Animation10snapToLandEv)
        *(.text._ZN3e6411character3d9Animation10snapToFallEv)
        *(.text._ZN3e6411character3d9Animation20snapRollToLocomotionEb)
        *(.text._ZN3e6411character3d9Animation12setSwimSpeedEPKNS0_13AnimationNodeEf)
        *(.text._ZN3e6411character3d8movementL11setClimbingEPNS_11Character3DEPNS0_15MovementCommandEf)
        *(.text._ZN3e6411character3d8movementL11setSwimmingEPNS_11Character3DEPNS0_15MovementCommandEf)
        *(.text._ZN3e6411character3d8movementL10setRollingEPNS_11Character3DEPNS0_15MovementCommandEf)
        *(.text._ZN3e6411character3d8movementL10setFallingEPNS_11Character3DEPNS0_15MovementCommandEf)
        *(.text._ZN3e6411character3d8movement12isCoyoteOpenEPKNS_11Character3DE)
        *(.text._ZN3e6411character3d8movement14isChargingJumpEPKNS_11Character3DE)
        *(.text._ZN3e6411character3d7physicsL13floorDistanceEPKNS_11Character3DEPKNS_12PhysicsWorldE)
        *(.text._ZN3e6411character3d8collider4initEPNS0_8ColliderEff)
        *(.text._ZN3e6411character3d8collider11setVerticalEPNS0_8ColliderEPKNS_7Vector3E)
        *(.text._ZN3e6411character3d7physics10createBodyEPNS_11Character3DEPNS_12PhysicsWorldE)
        *(.text._ZN3e6421skeletonModifiers_addEPNS_17SkeletonModifiersEPFvP11T3DSkeletonPvES4_)
        *(.text._ZN3e6424springBones_resolveChainEPK11T3DSkeletonPKNS_14SpringBonesDefEPsh)
        *(.text._ZN3e6415springBone_initEPNS_10SpringBoneEPK11T3DSkeletonshPKNS_14SpringBonesDefEPKNS_15RenderTransformE)
        *(.text._ZN3e6411character3d6weapon5equipEPNS_11Character3DEhPKNS0_9WeaponDefE)
        *(.text._ZN3e6411character3d6weapon5cycleEPNS_11Character3DEa)
        *(.text._ZN3e648entity2d6createEPKNS0_3DefE)
        *(.text._ZN3e648entity3d6createEPKNS0_3DefE)
        *(.text._ZN3e648entity3d7destroyEPNS_8Entity3DE)
        *(.text._ZN3e648entity3d9playSoundEPKNS_8Entity3DEhPKNS_7Vector3Ef)
        *(.text._ZN3e648entity3d17colliderTransformEPKNS0_3DefE)
        *(.text._ZN3e648entity3d13attachPhysicsEPNS_8Entity3DEPKNS0_3DefEPNS_12PhysicsWorldE)
        *(.text._ZN3e646player4initEv)
        *(.text._ZN3e646player14setCharacter3DEPNS_11Character3DEPKNS_11character3d14ControlBindingE)
        *(.text._ZN3e646player14setCharacter2DEPNS_11Character2DEPKNS_11character2d14ControlBindingE)
        *(.text._ZN3e646player17switchCharacter3DENS_8PlayerIDEa)
        *(.text._ZN3e6411character2d7control6updateEPNS_11Character2DEPNS0_15MovementCommandEPKNS0_8ControlsE)
        *(.text._ZN3e6410controller5startEv)
        *(.text._ZN3e648controls4bindEPKNS0_3DefEPKNS_10Scene3DDefE)
        *(.text._ZN3e648controls6bind2DEPKNS0_3DefEPKNS_10Scene2DDefE)
        *(.text._ZN3e646player21setCharacter2DControlENS_8PlayerIDE)
        *(.text._ZN3e6414font_loadAssetEh)
        *(.text._ZN3e6416font_unloadAssetEh)
        *(.text._ZN3e649text_drawEPKNS_4TextENS_7Vector2E)
        *(.text._ZN3e64L22material_textureEqualsEPK18T3DMaterialTextureS2_)
        *(.text._ZN3e64L19mesh_recordGeometryEPNS_4MeshE)
        *(.text._ZN3e64L20mesh_setPartMatricesEPNS_4MeshEh.part.0)
        *(.text._ZN3e6415mesh_initBoundsEPNS_4MeshE)
        *(.text._ZN3e6411mesh_recordEPNS_4MeshEPKPKchPK9T3DMat4FP)
        *(.text._ZN3e6412mesh_releaseEPNS_4MeshE)
        *(.text._ZN3e6413mesh_findPartEPKNS_4MeshEPKc)
        *(.text._ZN3e6419mesh_setPartVisibleEPNS_4MeshEhb)
        *(.text._ZN3e6414mesh_setDeformEPNS_4MeshEPKNS_7Vector3ES4_PKhtf)
        *(.text._ZN3e6419shape_drawRectangleEPKNS_9RectangleENS_7Vector2ES3_)
        *(.text._ZN3e6417sprite_isLoadableEPKNS_6SpriteEf)
        *(.text._ZN3e6416sprite_drawTiledEPKNS_6SpriteENS_7Vector2ES3_)
        *(.text._ZN3e6411sprite_drawEPKNS_6SpriteENS_7Vector2ES3_f)
        *(.text._ZN3e6415meshDeform_bindEPNS_10MeshDeformEP8T3DModelPKNS_7Vector3ES6_tf)
        *(.text._ZN3e6417meshDeform_deleteEPNS_10MeshDeformE)
        *(.text._ZN3e6412water_createEPKNS_8WaterDefE)
        *(.text._ZN3e6422water_getSurfaceHeightEPKNS_5WaterEff)
        *(.text._ZN3e64L25water_volumeSurfaceHeightEPKvff)
        *(.text._ZN3e6417water_bindPhysicsEPNS_5WaterEPNS_9RigidBodyEPNS_12PhysicsWorldE)
        *(.text._ZN3e6421water_getBoundSurfaceEPKNS_9RigidBodyE)
        *(.text._ZN3e6411water_clearEv)
        *(.text._ZN3e6420renderTransform_initEPNS_15RenderTransformE)
        *(.text._ZN3e648fog_initEPKNS_6FogDefE)
        *(.text._ZN3e6410light_initEPKNS_8LightDefE)
        *(.text._ZN3e6412scene3d_loadEPKNS_10Scene3DDefE)
        *(.text._ZN3e6414scene3d_unloadEv)
        *(.text._ZN3e6422scene3d_getCharacter3DEh)
        *(.text._ZN3e646camera4initEPNS_6CameraE)
        *(.text._ZN3e646camera13setViewTargetEPNS_6CameraEPKNS_7Vector3Ef)
        *(.text._ZN3e648camera2dL9setLimitsEPNS_8Camera2DEPNS_7Vector2E.part.0)
        *(.text._ZN3e648camera2d7setZoomEPNS_8Camera2DEf)
        *(.text._ZN3e648camera2d4initEPNS_8Camera2DEPKNS0_3DefE)
        *(.text._ZN3e648camera2d6updateEPNS_8Camera2DENS_7Vector2Eff)
        *(.text._ZN3e646camera9springArm6getYawEPKNS_6CameraE)
        *(.text._ZN3e646camera9springArm4initEPNS_6CameraEPKNS0_12SpringArmDefE)
        *(.text._ZN3e64L18viewport_applyModeEv)
        *(.text._ZN3e6413viewport_initEv)
        *(.text._ZN3e6415viewport_open3DEv)
        *(.text._ZN3e6416viewport_setModeEPKNS_15ViewportModeDefE)
        *(.text._ZN3e64L29particleBuffer_drawWithMatrixEPKNS_14ParticleBufferEPK9T3DMat4FPb)
        *(.text._ZN3e6413particles_addEPKNS_8ParticleE)
        *(.text._ZN3e6421particleBuffer_createENS_12ParticleTypeEm)
        *(.text._ZN3e64L13sound_panningEPKNS_8SoundDefEPKNS_7Vector3Ef.part.0.isra.0)
        *(.text._ZN3e64L18sound_startEmitterEPNS_17SoundEmitterStateEff)
        *(.text._ZN3e6410sound_initEv)
        *(.text._ZN3e6410sound_loadEPKNS_8SoundDefE)
        *(.text._ZN3e6412sound_unloadEPNS_5SoundE)
        *(.text._ZN3e6410sound_playEPKNS_5SoundEPKNS_7Vector3Eff)
        *(.text._ZN3e6421sound_setListenerModeENS_17SoundListenerModeE)
        *(.text._ZN3e649game_initEv)
        *(.text._ZN3e64L14gameState_loadEh)
        *(.text._ZN3e64L16gameState_unloadEh)
        *(.text._ZN3e6410game_startEPKNS_12GameStateDefEhh)
        *(.text._ZN3e6414scene2d_unloadEv)
        *(.text._ZN3e6424scene2d_updateCharactersEf)
        *(.text._ZN3e6420scene2d_updateCameraEPKNS_11Character2DEf)
        *(.text._ZN3e6417scene2d_getEntityEPNS_7Scene2DEhh)
        *(.text._ZN3e6422scene2d_getCharacter2DEh)
        *(.text._ZN3e6414stage2d_deleteEPNS_7Stage2DE)
        *(.text._ZN3e6424stage2d_setRenderContextEPKNS_7Stage2DEPKNS_8Camera2DEPNS_13RenderContextE)
        *(.text._ZN3e6415stage2d_isSolidEPKNS_7Stage2DEll)
        *(.text._ZN3e6411character2dL9setEntityEPNS_11Character2DE)
        *(.text._ZN3e6411character2d6createEPKNS0_3DefEPNS_8Entity2DE)
        *(.text._ZN3e6411character2d7destroyEPNS_11Character2DE)
        *(.text._ZN3e6411character2d6updateEPNS_11Character2DEf)
        *(.text._ZN3e6411character2d9animation4initEPNS_11Character2DEPKNS0_12AnimationDefE)
        *(.text._ZN3e6411character2d9animation9getSpriteEPKNS_11Character2DE)
        *(.text._ZN3e6411character2d8movementL10setFallingEPNS_11Character2DEPNS0_15MovementCommandEf)
        *(.text._ZN3e6411character2d8movement7setModeEPNS0_8MovementEh)
        *(.text._ZN3e6411character2d8movement12isLocomotionEh)
        *(.text._ZN3e6411character2d8movement12isCoyoteOpenEPKNS_11Character2DE)
        *(.text._ZN3e6411character2d8movement14isChargingJumpEPKNS_11Character2DE)
        *(.text._ZN3e6411Character2D14updateMovementEPNS_11character2d15MovementCommandEf)
        *(.text._ZN3e6411character2d7physicsL9cellRangeEPKNS_7Stage2DEffffPlS5_S5_S5_.isra.0)
        *(.text._ZN3e647ui_playEPKNS_11UIAnimationEb)
        *(.text._ZN3e6418ui_isTransitioningEv)
        *(.text._ZN3e64L17uiAnimation_fieldEPNS_7Scene2DEPKNS_16UIAnimationTrackE)
        *(.text._ZN3e64L22uiAnimation_applyTrackEPNS_7Scene2DEPKNS_16UIAnimationTrackEf)
        *(.text._ZN3e64L28uiAnimationPlayer_applyFrameEPNS_17UIAnimationPlayerEPNS_7Scene2DEf.isra.0)
        *(.text._ZN3e6417uiAnimation_applyEPNS_7Scene2DEPKNS_11UIAnimationEf)
        *(.text._ZN3e6423uiAnimationPlayer_startEPNS_17UIAnimationPlayerEPNS_7Scene2DEPKNS_11UIAnimationENS_19UIAnimationPlayModeEb)
        *(.text._ZN3e6418menuStack_getIndexEv)
        *(.text._ZN3e6419menuStack_moveIndexEaa)
        *(.text._ZN3e6412settings_getEv)
        *(.text._ZN3e6413settings_initEv)
        *(.text._ZN3e6413resource_loadEPKcNS_12ResourceTypeEPKv)
        *(.text._ZN3e6415resource_unloadEPv)
        *(.text._ZN3e6412debugUI_initEv)
        *(.text._ZL20gameState_enterPausev)
        *(.text._ZL20gameState_enterIntrov)
        *(.text._ZL22gameState_controlPausev)
        *(.text._ZL21gameState_updatePausev)
        *(.text._ZL24gameState_updateMainMenuv)
        *(.text._ZL21gameState_updateIntrov)
        *(.text._ZL24gameState_exitGameplay2Dv)
        *(.text._ZL29gameState_loadGameplay2DStageh)
        *(.text._ZL22gameState_exitGameplayv)
        *(.text._ZL23gameState_enterGameplayv)
        *(.text._ZL24gameState_controlCreditsv)
        *(.text._ZL22gameState_enterCreditsv)
        *(.text._ZL23gameState_updateCreditsv)
        *(.text._ZL27gameState_controlGameplay2Dv)
        *(.text._ZL25gameState_controlMainMenuv)
        *(.text._Z18demoStage_getCountv)
        *(.text._Z18demoStage_getSceneh)
        *(.text._Z19demoStage_getReturnh)
        *(.text._Z28credits_ui_setScrollVelocityf)
        *(.text._Z22credits_ui_resetScrollv)
        *(.text._Z23credits_ui_updateScrollf)
        *(.text._ZL28staminaWheel_setRenderStateAv)
        *(.text._Z18stamina_wheel_loadv)
        *(.text._Z20stamina_wheel_unloadv)
        *(.text._Z18stamina_wheel_initv)
        *(.text.t3d_mat4fp_from_srt_euler)
        *(.text.t3d_tri_draw_sequence)
        *(.text.t3d_tri_draw_strip_generic)
        *(.text.t3d_init)
        *(.text.t3d_destroy)
        *(.text.t3d_vert_load)
        *(.text.t3d_light_set_directional)
        *(.text.t3d_state_set_drawflags)
        *(.text.t3d_state_set_vertex_fx)
        *(.text.t3d_tri_draw_strip_and_sync)
        *(.text.t3d_fog_set_range)
        *(.text.t3d_indexbuffer_convert)
        *(.text.set_texture)
        *(.text.texture_cache_free)
        *(.text.t3d_model_load)
        *(.text.t3d_model_make_object_vert_placeholder)
        *(.text.t3d_model_draw_object)
        *(.text.t3d_model_draw_material)
        *(.text.t3d_model_free)
        *(.text.t3d_model_get_animation)
        *(.text.t3d_model_iter_next)
        *(.text.t3d_skeleton_clone)
        *(.text.t3d_skeleton_reset)
        *(.text.t3d_skeleton_create_buffered)
        *(.text.t3d_skeleton_find_bone)
        *(.text.t3d_skeleton_destroy)
        *(.text.t3d_anim_create)
        *(.text.t3d_anim_attach)
        *(.text.t3d_anim_destroy)
        *(.text.t3d_anim_set_time)
        *(.text.tpx_dmem_set_u32)
        *(.text.tpx_matrix_stack)
        *(.text.tpx_particle_draw_generic_s8)
        *(.text.tpx_state_from_t3d)
        *(.text.tpx_state_set_scale)
        *(.text.tpx_state_set_tex_params)
        *(.text.tpx_particle_draw_s16)
        *(.text.tpx_particle_draw_tex_s8)
        *(.text.tpx_particle_draw_tex_s16)
        *(.text.tpx_init)
        *(.text.data_cache_hit_writeback_invalidate)
        *(.text.inst_cache_hit_invalidate)
        *(.text.malloc_uncached)
        *(.text.malloc_uncached_aligned)
        *(.text.free_uncached)
        *(.text.get_memory_size)
        *(.text.wait_ms)
        *(.text.die)
        *(.text.sys_get_version)
        *(.text.startup.__init_cop1)
        *(.text.sys_hw_memset)
        *(.text.sys_hw_memset16)
        *(.text.sys_hw_memset32)
        *(.text.startup.__n64sys_hwmemset_emucheck)
        *(.text.__mi_memset)
        *(.text.__MI_BB_handler)
        *(.text.__CART_handler)
        *(.text.register_AI_handler)
        *(.text.register_VI_handler)
        *(.text.register_PI_handler)
        *(.text.register_DP_handler)
        *(.text.register_SI_handler)
        *(.text.register_SP_handler)
        *(.text.register_TI_handler)
        *(.text.set_AI_interrupt)
        *(.text.set_PI_interrupt)
        *(.text.set_DP_interrupt)
        *(.text.set_SP_interrupt)
        *(.text.set_TI_interrupt)
        *(.text.startup.__init_interrupts)
        *(.text.reseed_from_entropy)
        *(.text.getentropy64)
        *(.text.getentropy32)
        *(.text.startup.__rand_init)
        *(.text.__stderr_write)
        *(.text.isviewer_write)
        *(.text.debugfv)
        *(.text.debug_init_usblog)
        *(.text.debug_init_emulog)
        *(.text.debugf)
        *(.text.debug_assert_func_f)
        *(.text.debug_hexdump)
        *(.text.__debug_backtrace)
        *(.text._ZL17terminate_handlerv)
        *(.text._Z16__debug_init_cppv)
        *(.text.usb_64drive_read)
        *(.text.usb_64drive_poll)
        *(.text.usb_everdrive_readusb)
        *(.text.usb_everdrive_poll)
        *(.text.usb_everdrive_write)
        *(.text.usb_sc64_poll)
        *(.text.usb_sendheartbeat)
        *(.text.usb_64drive_wait)
        *(.text.usb_64drive_write)
        *(.text.usb_sc64_execute_cmd)
        *(.text.usb_sc64_write)
        *(.text.rompak_get_header)
        *(.text.walkfn.0)
        *(.text.rompak_walk)
        *(.text.rompak_search_ext)
        *(.text.rompak_version_parse)
        *(.text.startup.__rompak_init)
        *(.text.get_next_token)
        *(.text.lookup_file)
        *(.text.__close)
        *(.text.__dfs_set_errno)
        *(.text.__fstat)
        *(.text.find_dirent)
        *(.text.recurse_path)
        *(.text.__dfs_findnext)
        *(.text.__findnext)
        *(.text.__dfs_init)
        *(.text.__dfs_findfirst)
        *(.text.__findfirst)
        *(.text.__stat)
        *(.text.__lseek)
        *(.text.dfs_open)
        *(.text.__open)
        *(.text.dfs_read)
        *(.text.__read)
        *(.text.dfs_init)
        *(.text.audio_carve_buffers)
        *(.text.audio_init)
        *(.text.audio_set_buffer_granularity)
        *(.text.audio_get_frequency)
        *(.text.apply_display_vi_config.isra.0)
        *(.text.display_init)
        *(.text.display_close)
        *(.text.display_get_height)
        *(.text.tex_format_name)
        *(.text.surface_alloc)
        *(.text.surface_free)
        *(.text.seekfn_cmp)
        *(.text.closefn_none)
        *(.text.closefn_cmp)
        *(.text.readfn_cmp)
        *(.text.readfn_none)
        *(.text.must_open.part.0)
        *(.text.asset_read_header)
        *(.text.__asset_init_compression_lvl2)
        *(.text.must_open)
        *(.text.decompress_full)
        *(.text.asset_read)
        *(.text.asset_load)
        *(.text.asset_fdopen)
        *(.text.asset_fopen)
        *(.text.__clip_blit)
        *(.text.color_to_packed32)
        *(.text.graphics_set_default_font)
        *(.text.graphics_draw_character)
        *(.text.rsp_load_code)
        *(.text.rsp_load_data)
        *(.text.rsp_load)
        *(.text.rsp_read_code)
        *(.text.rsp_read_data)
        *(.text.__rsp_run_async)
        *(.text.rsp_wait)
        *(.text.rsp_run)
        *(.text.cb.3)
        *(.text.inspector_print_backtrace)
        *(.text.inspector_page_threads)
        *(.text.inspector_page_version)
        *(.text.inspector_page_gpr)
        *(.text.version_walk)
        *(.text.inspector)
        *(.text.handler.4)
        *(.text.inspector_page_disasm)
        *(.text.inspector_page_exception)
        *(.text.__inspector_add_page)
        *(.text.__inspector_exception)
        *(.text.__inspector_assertion)
        *(.text.__inspector_cppexception)
        *(.text.startup.__inspector_init)
        *(.text.__sprite_ext)
        *(.text.sprite_get_lod_pixels.part.0)
        *(.text.__sprite_upgrade)
        *(.text.sprite_load_buf)
        *(.text.sprite_load)
        *(.text.sprite_free)
        *(.text.sprite_get_pixels)
        *(.text.sprite_get_lod_pixels)
        *(.text.sprite_get_detail_pixels)
        *(.text.sprite_get_palette)
        *(.text.sprite_get_palette_used_colors)
        *(.text.sprite_get_texparms)
        *(.text.sprite_fits_tmem)
        *(.text.sprite_is_shq)
        *(.text.pi_interrupt)
        *(.text.pi_manual_interrupt_poll)
        *(.text.pi_enqueue)
        *(.text.dma_wait_and_disable_interrupts)
        *(.text.dma_read_raw_async)
        *(.text.dma_read_async)
        *(.text.dma_wait_started)
        *(.text.dma_wait_finished)
        *(.text.dma_read)
        *(.text.dma_write)
        *(.text.io_read)
        *(.text.io_write)
        *(.text.startup.__dma_init)
        *(.text.new_timer_context)
        *(.text.is_unmapped_kx64)
        *(.text.__get_exception_name.isra.0)
        *(.text.__exception_dump_header)
        *(.text.__exception_dump_gpr)
        *(.text.__exception_dump_fpr)
        *(.text.exception_default_handler)
        *(.text.__onCriticalException)
        *(.text.register_syscall_handler)
        *(.text.__onSyscallException)
        *(.text.inspector_page_modules)
        *(.text.kthread_free)
        *(.text.__thlist_add.part.0)
        *(.text.startup.__kernel_tls_init)
        *(.text.__kthread_check_overflow)
        *(.text.kmutex_unlock_internal)
        *(.text.__kthread_syscall_schedule)
        *(.text.kthread_current)
        *(.text.kthread_yield)
        *(.text.kthread_suspend)
        *(.text.kthread_backtrace)
        *(.text.kmutex_init)
        *(.text.kmutex_destroy)
        *(.text.kmutex_unlock)
        *(.text.__kcond_broadcast_isr)
        *(.text.kcond_wait)
        *(.text.kirq_begin_wait_pi)
        *(.text.mixer_ch_bounds)
        *(.text.mixer_refresh_max_ns)
        *(.text.mixer_fold_volumes)
        *(.text.mixer_channel_window)
        *(.text.mixer_ramp_at)
        *(.text.mixer_ch_apply_freq)
        *(.text.mixer_vadpcm_seek)
        *(.text.mixer_ch_unpin_loop)
        *(.text.mixer_ramp_exp)
        *(.text.waveform_wrap_wpos.part.0)
        *(.text.mixer_vadpcm_frame_bytes.part.0)
        *(.text.mixer_large_loop_wrap)
        *(.text.waveform_read)
        *(.text.mixer_calc_buffer_size)
        *(.text.mixer_wave_fits)
        *(.text.mixer_loop_fits)
        *(.text.mixer_ramp_to)
        *(.text.__mixer_inflight_samples)
        *(.text.mixer_ch_set_freq)
        *(.text.mixer_ch_set_vol)
        *(.text.mixer_ch_set_vol_ramp)
        *(.text.mixer_ch_set_gain)
        *(.text.mixer_ch_set_gain_ramp)
        *(.text.mixer_ch_stop)
        *(.text.mixer_ch_playing_waveform)
        *(.text.mixer_ch_playing)
        *(.text.mixer_ch_set_priority)
        *(.text.mixer_ch_set_limits)
        *(.text.mixer_init)
        *(.text.__mixer_rdram_copy)
        *(.text.mixer_remove_event)
        *(.text.samplebuffer_copy)
        *(.text.samplebuffer_align_len.isra.0)
        *(.text.samplebuffer_recalc_size)
        *(.text.samplebuffer_dma_wait)
        *(.text.samplebuffer_init)
        *(.text.samplebuffer_set_unit_bytes)
        *(.text.samplebuffer_set_waveform)
        *(.text.samplebuffer_close)
        *(.text.samplebuffer_prefetch)
        *(.text.samplebuffer_append)
        *(.text.samplebuffer_flush)
        *(.text.wav64_none_init)
        *(.text.wav64_none_get_bitrate)
        *(.text.wav64_none_read)
        *(.text.wav64_load)
        *(.text.wav64_play)
        *(.text.wav64_set_loop)
        *(.text.wav64_close)
        *(.text.wav64_vadpcm_find_skippoint)
        *(.text.huffv_decompress)
        *(.text.waveform_vadpcm_read)
        *(.text.wav64_vadpcm_preload)
        *(.text.wav64_vadpcm_init)
        *(.text.wav64_vadpcm_close)
        *(.text.wav64_vadpcm_get_bitrate)
        *(.text.wav64_vadpcm_adjust_seek)
        *(.text.joypad_gcn_origin_callback)
        *(.text.joybus_input_read_n64_controllers)
        *(.text.joypad_device_reset)
        *(.text.joypad_read_n64_inputs)
        *(.text.joypad_init)
        *(.text.rspq_sp_interrupt)
        *(.text.rspq_init_context.constprop.0)
        *(.text.rspq_chain_free.constprop.0)
        *(.text.rspq_crash_handler)
        *(.text.rspq_assert_handler)
        *(.text.rspq_chain_next.isra.0)
        *(.text.rspq_init)
        *(.text.rspq_block_begin_reuse)
        *(.text.rspq_block_end)
        *(.text.rspq_block_free)
        *(.text.rspq_syncpoint_new)
        *(.text.rspq_overlay_register_internal)
        *(.text.rspq_overlay_register)
        *(.text.rspq_overlay_register_static)
        *(.text.rspq_overlay_unregister)
        *(.text.rspq_highpri_sync)
        *(.text.rspq_syncpoint_wait)
        *(.text.rspq_wait)
        *(.text.rspq_overlay_get_state)
        *(.text.rdpq_assert_handler)
        *(.text.rdpq_set_tile)
        *(.text.__rdpq_autosync_use)
        *(.text.rdpq_config_set)
        *(.text.rdpq_config_disable)
        *(.text.__rdpq_block_begin)
        *(.text.__rdpq_block_recycle)
        *(.text.__rdpq_block_next_buffer)
        *(.text.__rdpq_block_end)
        *(.text.__rdpq_block_run_maybe_rdp)
        *(.text.__rdpq_block_free)
        *(.text.__rdpq_block_reserve)
        *(.text.__rdpq_block_update)
        *(.text.rdpq_set_blend_color)
        *(.text.rdpq_set_env_color)
        *(.text.rdpq_set_prim_color)
        *(.text.rdpq_set_texture_image)
        *(.text.__rdpq_set_other_modes)
        *(.text.rdpq_init)
        *(.text.__rdpq_change_other_modes)
        *(.text.rdpq_set_tile_autotmem)
        *(.text.rdpq_sync_load)
        *(.text.rdpq_triangle_rsp)
        *(.text.__rdpq_texture_rectangle_scaled_offline)
        *(.text.rdpq_mode_blender)
        *(.text.rdpq_mode_alphacompare)
        *(.text.rdpq_mode_combiner)
        *(.text.sprite_upload_palette)
        *(.text.__rdpq_sprite_upload)
        *(.text.rdpq_sprite_upload)
        *(.text.rdpq_sprite_blit)
        *(.text.texload_set_rect)
        *(.text.tex_xblit_norotate_noscale)
        *(.text.tex_xblit_norotate)
        *(.text.tex_xblit_xform)
        *(.text.draw_cb.0)
        *(.text.draw_cb.1)
        *(.text.draw_cb.2)
        *(.text.tex_xblit)
        *(.text.rdpq_load_block.part.0)
        *(.text.texload_tile)
        *(.text.texload_tile_4bpp)
        *(.text.texload_block_4bpp)
        *(.text.texload_block)
        *(.text.tex_loader_load)
        *(.text.ltd_texloader)
        *(.text.rdpq_tex_upload_sub)
        *(.text.rdpq_tex_reuse_sub)
        *(.text.rdpq_tex_reuse)
        *(.text.__rdpq_tex_blit)
        *(.text.rdpq_tex_blit)
        *(.text.rdpq_tex_upload_tlut)
        *(.text.rdpq_tex_multi_begin)
        *(.text.rdpq_tex_multi_end)
        *(.text.rdpq_attach.part.0)
        *(.text.__rdpq_font_glyph_sparse.isra.0)
        *(.text.rdpq_font_load)
        *(.text.__rdpq_font_kerning)
        *(.text.rdpq_font_style)
        *(.text.__rdpq_font_load_builtin_1)
        *(.text.rdpq_text_unregister_font)
        *(.text.char_compare)
        *(.text.paragraph_extend)
        *(.text.__rdpq_paragraph_builder_newline)
        *(.text.paragraph_wrap)
        *(.text.transform_point)
        *(.text.__rdpq_xform_init)
        *(.text.rdpq_xform_mtx_mult)
        *(.text.rdpq_xform_mult_srt)
        *(.text.rdpq_xform_push)
        *(.text.rdpq_xform_pop)
        *(.text.rdpq_xform_texture_rectangle)
        *(.text.fm_exp2f)
        *(.text.fm_mat3_from_srt)
        *(.text.decompress_lz4_full_inplace)
        *(.text.decompress_lz4_init)
        *(.text.decompress_lz4_reset)
        *(.text.decompress_lz4_full_fast)
        *(.text.__ringbuf_init)
        *(.text.__ringbuf_write)
        *(.text.__ringbuf_copy)
        *(.text.__lookahead_buf_refill)
        *(.text.__lookahead_buf_reset)
        *(.text.__lookahead_buf_init)
        *(.text.decompress_aplib_init)
        *(.text.decompress_aplib_reset)
        *(.text.decompress_aplib_read)
        *(.text.decompress_aplib_full_inplace)
        *(.text.shr_read_u32be)
        *(.text.decompress_shrinkler_full_inplace)
        *(.text.decompress_shrinkler_init)
        *(.text.__symbolize)
        *(.text.__bt_analyze_func)
        *(.text.backtrace_foreach.constprop.0)
        *(.text.backtrace)
        *(.text.__backtrace_from)
        *(.text.backtrace_symbols_cb)
        *(.text.backtrace_frame_print)
        *(.text.symt_open)
        *(.text.symt_find_symbol)
        *(.text.symt_get_func_name)
        *(.text.symt_get_file_name)
        *(.text.__utf8_decode)
        *(.text.__read_varint_u64)
        *(.text.__read_varint_s64)
        *(.text.__set_output)
        *(.text.vi_write_end_forced)
        *(.text.vi_set_interlaced)
        *(.text.vi_set_aa_mode)
        *(.text.vi_set_divot)
        *(.text.vi_set_dedither)
        *(.text.vi_set_gamma)
        *(.text.vi_set_output)
        *(.text.vi_set_borders)
        *(.text.vi_calc_borders)
        *(.text.vi_wait_vblank)
        *(.text.vi_install_vblank_handler)
        *(.text.vi_uninstall_vblank_handler)
        *(.text.vi_set_timing_preset)
        *(.text.vi_reset)
        *(.text.vi_init)
        *(.text.__console_render.part.0)
        *(.text.__console_write)
        *(.text.console_init)
        *(.text.console_render)
        *(.text.console_set_debug)
        *(.text.startup.__joybus_init)
        *(.text.joybus_exec)
        *(.text.joybus_register_detection_callback)
        *(.text.joybus_init)
        *(.text.joybus_detect_now)
        *(.text.decompress_aplib_full_fast)
        *(.text.decompress_shrinkler_full_fast)
        *(.text.__get_fs_link_by_name)
        *(.text.attach_filesystem)
        *(.text.fstat)
        *(.text.getpid)
        *(.text.isatty)
        *(.text.kill)
        *(.text.open)
        *(.text.read)
        *(.text.sbrk)
        *(.text.sbrk_top)
        *(.text.ioctl)
        *(.text.write)
        *(.text._flush_cache)
        *(.text.__assert_func)
        *(.text.__retarget_lock_init_recursive)
        *(.text.__retarget_lock_close_recursive)
        *(.text.__cxa_begin_catch)
        *(.text.__cxa_end_catch)
        *(.text._ZL16get_adjusted_ptrPKSt9type_infoS1_PPv)
        *(.text._ZL28read_encoded_value_with_basehjPKhPj)
        *(.text._ZL21base_of_encoded_valuehP15_Unwind_Context)
        *(.text._ZL17parse_lsda_headerP15_Unwind_ContextPKhP16lsda_header_info)
        *(.text._ZL20check_exception_specP16lsda_header_infoPKSt9type_infoPvl)
        *(.text._ZL33__gxx_dependent_exception_cleanup19_Unwind_Reason_CodeP17_Unwind_Exception)
        *(.text._ZNSt15__exception_ptr13exception_ptr9_M_addrefEv)
        *(.text._ZNSt15__exception_ptr13exception_ptr10_M_releaseEv)
        *(.text._ZSt17current_exceptionv)
        *(.text._ZSt17rethrow_exceptionNSt15__exception_ptr13exception_ptrE)
        *(.text._ZN10__cxxabiv111__terminateEPFvvE)
        *(.text.unlikely._ZSt9terminatev)
        *(.text._ZSt13set_terminatePFvvE)
        *(.text._ZSt13get_terminatev)
        *(.text._ZN10__cxxabiv120__si_class_type_infoD2Ev)
        *(.text._ZNK10__cxxabiv120__si_class_type_info20__do_find_public_srcEiPKvPKNS_17__class_type_infoES2_)
        *(.text._ZNK10__cxxabiv120__si_class_type_info11__do_upcastEPKNS_17__class_type_infoEPKvRNS1_15__upcast_resultE)
        *(.text._ZN9__gnu_cxx27__verbose_terminate_handlerEv)
        *(.text._ZNK10__cxxabiv117__class_type_info11__do_upcastEPKS0_PPv)
        *(.text._ZNK10__cxxabiv117__class_type_info20__do_find_public_srcEiPKvPKS0_S2_)
        *(.text._ZN10__cxxabiv117__class_type_infoD0Ev)
        *(.text._ZNK10__cxxabiv117__class_type_info11__do_upcastEPKS0_PKvRNS0_15__upcast_resultE)
        *(.text._ZNK10__cxxabiv117__class_type_info10__do_catchEPKSt9type_infoPPvj)
        *(.text._ZNK10__cxxabiv117__class_type_info12__do_dyncastEiNS0_10__sub_kindEPKS0_PKvS3_S5_RNS0_16__dyncast_resultE)
        *(.text._ZdlPvj)
        *(.text._ZN12_GLOBAL__N_14pool4freeEPv.constprop.0)
        *(.text._ZN12_GLOBAL__N_14pool8allocateEj.constprop.0)
        *(.text.__cxa_free_exception)
        *(.text.__cxa_allocate_dependent_exception)
        *(.text.__cxa_free_dependent_exception)
        *(.text.startup._GLOBAL__sub_I__ZN9__gnu_cxx9__freeresEv)
        *(.text.unlikely.__cxa_call_terminate)
        *(.text.__cxa_current_exception_type)
        *(.text._ZdlPv)
        *(.text.*)
        KEEP(*(keep.text.*))
        *(.init)
        *(.fini)
        *(.gnu.linkonce.t.*)
        . = ALIGN(16);
        __text_end  = .;
    } :main

   .eh_frame_hdr : { *(.eh_frame_hdr) }
   .eh_frame : { 
        __EH_FRAME_BEGIN__ = .; /* Define symbol for accessing eh_frame section */
        KEEP (*(.eh_frame)) 
    }
   .gcc_except_table : { *(.gcc_except_table*) } 
   .jcr : { KEEP (*(.jcr)) } 

    .rodata : {
        *(.rdata)
        *(.rodata)
        *(.rodata.*)
        KEEP(*(keep.rodata.*))
        *(.gnu.linkonce.r.*)
        . = ALIGN(4);
        __tdata_align = .;
        LONG (ALIGNOF(.tdata));
        . = ALIGN(8);
    }

    /* This is important to keep __CTOR_END__ consistent */
    . = ALIGN(4);

    .ctors : {
        __CTOR_LIST__ = .;
        /* Actually we should place the count here like;

        LONG((__CTOR_END__ - __CTOR_LIST__) / 4 - 2)

        but g++ seem to already do this (though incorrectly placing an 0xFFFFFFFF)
        and that breaks things if we also add it. Ideally this should be parsed
        by the code but we already know the end as well.

        The new build system links everything via g++ by default and should use
        __wrap___do_global_ctors and enables it via the --wrap linker option.
        When linking with ld, we should use __do_global_ctors, which is the default
        if you don't provide the --wrap option. */
        KEEP(*(EXCLUDE_FILE (*crtend.o) .ctors))
        KEEP(*(SORT(.ctors.*)))
        KEEP(*crtend.o(.ctors))
         /* Similarly we should have a;

        LONG(0)

        here, and g++ seem to insert it at __CTOR_END__ */
        __CTOR_END__ = .;
    }

    . = ALIGN(8);

    /* Data section has relocation address at start of RAM in cached,
    * unmapped memory, but is loaded just at the end of the text segment,
    * and must be copied to the correct location at startup
    * Gather all initialised data together.  The memory layout
    * will place the global initialised data at the lowest addrs.
    * The lit8, lit4, sdata and sbss sections have to be placed
    * together in that order from low to high addrs with the _gp symbol
    * positioned (aligned) at the start of the sdata section.
    * We then finish off with the standard bss section
    */
    .data : {
        __data_start = .;
        *(.data)
        *(.data.*)
        KEEP(*(keep.data.*))
        *(.gnu.linkonce.d.*)
        . = ALIGN(8);
    }
    
    .tdata : {
        __tls_base = .;
        __tdata_start = .;
        *(.tdata)
        *(.tdata.*)
        *(.gnu.linkonce.td.*)
        __tdata_end = .;
    }
    
    .tbss : {
        __tbss_start = .;
        *(.tbss)
        *(.tbss.*)
        *(.gnu.linkonce.tb.*)
        . = ALIGN(8);
        __tbss_end = .;
        __tls_end = .;
    }
    
    /* Fix dot for TBSS Sections */
    . = .+(__tbss_end-__tbss_start);
    
    /* Small data START */

    .sdata : {
        _gp = . + 0x8000;
        *(.sdata)
        *(.sdata.*)
        *(.gnu.linkonce.s.*)
        . = ALIGN(8);
    }

    .lit8 : {
        *(.lit8)
        . = ALIGN(8);
    }
    .lit4 : {
        *(.lit4)
        . = ALIGN(8);
    }

    . = ALIGN(8);
    __data_end = .;

    /* Here the ROM is finished. The rest is just in RAM */
    . = ALIGN(8);
    __rom_end = .;

    .sbss : {
         __bss_start = .;
        *(.sbss)
        *(.sbss.*)
        *(.gnu.linkonce.sb.*)
        *(.scommon)
        *(.scommon.*)
    }

    /* Small data END */

    . = ALIGN(8);
    .bss : {
        *(.bss)
        *(.bss*)
        *(.gnu.linkonce.b.*)
        *(COMMON)
        . = ALIGN(8);
        __th_tdata_copy = .;
        . = .+(__tdata_end-__tdata_start);
        . = ALIGN(8);
         __bss_end = .;
    }

    . = ALIGN(8);

    /* Deprecated */
    end = .;
}

/* Give an assert for a too huge binary. The maximum allowed size here is 8 MiB,
   minus the space for the stack and the initial low memory section. 
   Notice the exact size doesn't matter much: we want to detect mistakes that
   would be much harder to find at runtime when no heap is available... */
ASSERT(end - __text_start <= 8*1024*1024 - 64*1024 - 1024, "ERROR: the generated ELF is too big for N64 memory")
